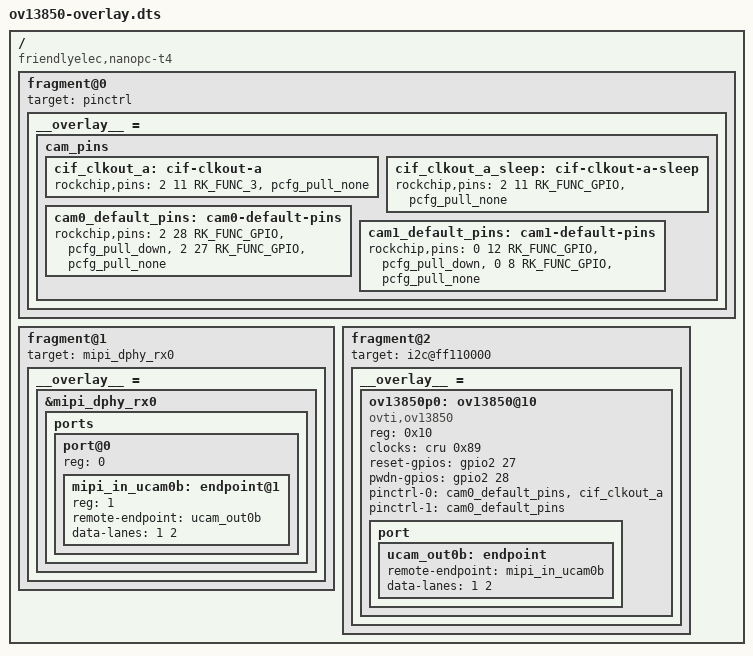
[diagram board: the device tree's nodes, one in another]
/*
 * Overlay device tree to include the OV13850 camera sensor to an NanoPC-T4 SBC with an rk3399 SoC.
 */

/dts-v1/;
/plugin/;

/ {
	compatible = "friendlyelec,nanopc-t4", "rockchip,rk3399";

	fragment@0 {
		target = <&pinctrl>;

		__overlay__ = {
			cam_pins {
				cif_clkout_a: cif-clkout-a {
					rockchip,pins = <2 11 RK_FUNC_3 &pcfg_pull_none>;
				};

				cif_clkout_a_sleep: cif-clkout-a-sleep {
					rockchip,pins = <2 11 RK_FUNC_GPIO &pcfg_pull_none>;
				};

				cam0_default_pins: cam0-default-pins {
					rockchip,pins =
						<2 28 RK_FUNC_GPIO &pcfg_pull_down>,
						<2 27 RK_FUNC_GPIO &pcfg_pull_none>;
				};

				cam1_default_pins: cam1-default-pins {
					rockchip,pins =
						<0 12 RK_FUNC_GPIO &pcfg_pull_down>,
						<0  8 RK_FUNC_GPIO &pcfg_pull_none>;
				};
			};
		};
	};

	fragment@1 {
		target = <&mipi_dphy_rx0>;

		__overlay__ = {
			&mipi_dphy_rx0 {
				status = "okay";

				ports {
					#address-cells = <1>;
					#size-cells = <0>;

					port@0 {
						reg = <0>;
						#address-cells = <1>;
						#size-cells = <0>;

						// mipi_in_ucam0a: endpoint@0 {
						// 	reg = <0>;
						// 	remote-endpoint = <&ucam_out0a>;
						// 	data-lanes = <1 2>;
						// };

						mipi_in_ucam0b: endpoint@1 {
							reg = <1>;
							remote-endpoint = <&ucam_out0b>;
							data-lanes = <1 2>;
						};
					};

					// port@1 {
					//	reg = <1>;
					//	#address-cells = <1>;
					//	#size-cells = <0>;

					//	dphy_rx0_out: endpoint@0 {
					//		reg = <0>;
					//		remote-endpoint = <&isp0_mipi_in>;
					//	};
					// };
				};
			};
		};
	};

	fragment@2 {
		target = <&i2c@ff110000>;

		__overlay__ = {
			ov13850p0: ov13850@10 {
				compatible = "ovti,ov13850";
				status = "okay";
				reg = <0x10>;
				clocks = <&cru 0x89>;
				clock-names = "xvclk";

				reset-gpios = <&gpio2 27 GPIO_ACTIVE_HIGH>;
				pwdn-gpios = <&gpio2 28 GPIO_ACTIVE_HIGH>;
				pinctrl-names = "rockchip,camera_default", "rockchip,camera_sleep";
				pinctrl-0 = <&cam0_default_pins &cif_clkout_a>;
				pinctrl-1 = <&cam0_default_pins>;

				port {
					ucam_out0b: endpoint {
						remote-endpoint = <&mipi_in_ucam0b>;
						data-lanes = <1 2>;
					};
				};
			};
		};
	};
}
